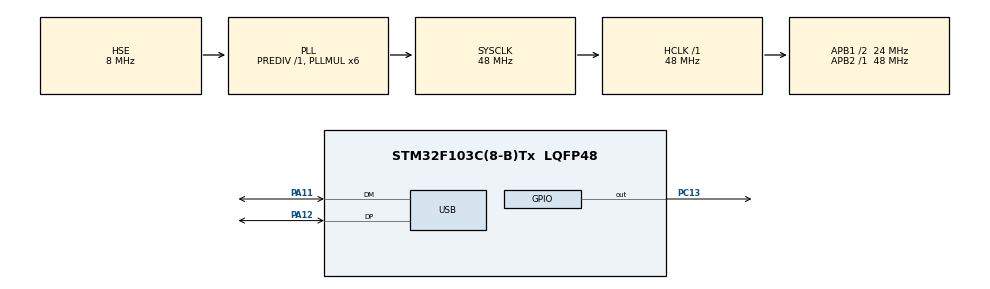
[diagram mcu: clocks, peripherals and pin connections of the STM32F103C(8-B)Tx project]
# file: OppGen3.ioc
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Mcu.Family=STM32F1
Mcu.Name=STM32F103C(8-B)Tx
Mcu.Package=LQFP48
NVIC.PriorityGroup=NVIC_PRIORITYGROUP_4
NVIC.USB_LP_CAN1_RX0_IRQn=true\:0\:0\:false\:false\:true\:false\:true
PA11.Mode=Device
PA11.Signal=USB_DM
PA12.Mode=Device
PA12.Signal=USB_DP
PA13.Mode=Serial_Wire
PA13.Signal=SYS_JTMS-SWDIO
PA14.Mode=Serial_Wire
PA14.Signal=SYS_JTCK-SWCLK
PC13-TAMPER-RTC.PinState=GPIO_PIN_SET
PC13-TAMPER-RTC.Signal=GPIO_Output
PD0-OSC_IN.Mode=HSE-External-Oscillator
PD0-OSC_IN.Signal=RCC_OSC_IN
PD1-OSC_OUT.Mode=HSE-External-Oscillator
PD1-OSC_OUT.Signal=RCC_OSC_OUT
ProjectManager.HeapSize=0x200
ProjectManager.StackSize=0x400
ProjectManager.TargetToolchain=SW4STM32
RCC.AHBFreq_Value=48000000
RCC.APB1CLKDivider=RCC_HCLK_DIV2
RCC.APB1Freq_Value=24000000
RCC.APB1TimFreq_Value=48000000
RCC.APB2Freq_Value=48000000
RCC.APB2TimFreq_Value=48000000
RCC.HCLKFreq_Value=48000000
RCC.PLLMUL=RCC_PLL_MUL6
RCC.SYSCLKFreq_VALUE=48000000
RCC.SYSCLKSource=RCC_SYSCLKSOURCE_PLLCLK
RCC.USBFreq_Value=48000000
USB_DEVICE.CLASS_NAME_FS=CDC
USB_DEVICE.VirtualMode=Cdc
USB_DEVICE.VirtualModeFS=Cdc_FS
VP_USB_DEVICE_VS_USB_DEVICE_CDC_FS.Mode=CDC_FS
board=custom

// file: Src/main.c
/* USER CODE BEGIN Header */
/*
 *===============================================================================
 *
 *                         OOOOOO
 *                       OOOOOOOOOO
 *      PPPPPPPPPPPPP   OOO      OOO   PPPPPPPPPPPPP
 *    PPPPPPPPPPPPPP   OOO        OOO   PPPPPPPPPPPPPP
 *   PPP         PPP   OOO        OOO   PPP         PPP
 *  PPP          PPP   OOO        OOO   PPP          PPP
 *  PPP          PPP   OOO        OOO   PPP          PPP
 *  PPP          PPP   OOO        OOO   PPP          PPP
 *   PPP         PPP   OOO        OOO   PPP         PPP
 *    PPPPPPPPPPPPPP   OOO        OOO   PPPPPPPPPPPPPP
 *     PPPPPPPPPPPPP   OOO        OOO   PPP
 *               PPP   OOO        OOO   PPP
 *               PPP   OOO        OOO   PPP
 *               PPP   OOO        OOO   PPP
 *               PPP    OOO      OOO    PPP
 *               PPP     OOOOOOOOOO     PPP
 *              PPPPP      OOOOOO      PPPPP
 *
 * @file:   main.c
 * @author: Hugh Spahr
 * @date:   9/21/2019
 *
 * @note:   Open Pinball Project
 *          Copyright© 2019, Hugh Spahr
 *
 *  This program is free software: you can redistribute it and/or modify
 *  it under the terms of the GNU General Public License as published by
 *  the Free Software Foundation, either version 3 of the License, or
 *  (at your option) any later version.
 *
 *  This program is distributed in the hope that it will be useful,
 *  but WITHOUT ANY WARRANTY; without even the implied warranty of
 *  MERCHANTABILITY or FITNESS FOR A PARTICULAR PURPOSE.  See the
 *  GNU General Public License for more details.
 *
 *  You should have received a copy of the GNU General Public License
 *  along with this program.  If not, see <http://www.gnu.org/licenses/>.
 *
 *===============================================================================
 */
/**
 * This is main file.  It initializes the tasks, and runs them.
 *
 *===============================================================================
 */
/* USER CODE END Header */

#include "main.h"
#include "usb_device.h"

/* USER CODE BEGIN Includes */
#include "Common/stdtypes.h"
#define GEN2G_INSTANTIATE
#include "Common/gen2glob.h"
#include "Common/neointf.h"
#include "Common/stdlintf.h"
#define INSTANTIATE_PROC
#include "Common/procdefs.h"
/* USER CODE END Includes */

void SystemClock_Config(void);
static void MX_GPIO_Init(void);

/* USER CODE BEGIN PFP */
/* HRS:  Debug */
void debug_save_nv_cfg();

/* Prototype declarations */
void timer_init();
void timer_overflow_isr();

void main_copy_flash_to_ram();
void main_call_wing_inits();

void digital_init();
void digital_task(void);
void digital_write_outputs();

void rs232proc_init();
void rs232proc_task();

void incand_task(void);

void fade_init();
void fade_start();
void fade_task();

void lampmtrx_task();

void servo_init();

/* USER CODE END PFP */

int main(void)
{

   /* MCU Configuration--------------------------------------------------------*/

   /* Reset of all peripherals, Initializes the Flash interface and the Systick. */
   HAL_Init();
#if GEN2G_DEBUG_PORT == 0
   __HAL_AFIO_REMAP_SWJ_DISABLE();
#endif

   /* Configure the system clock */
   SystemClock_Config();

   /* Initialize all configured peripherals */
   MX_GPIO_Init();
   MX_USB_DEVICE_Init();

   // HRS:  Start code here
   appStart.codeVers = GEN2G_CODE_VERS;

   /* Used for forcing the standard configuration onto the board.  If this is left on,
    * the programmed configuration will always be overwritten.
    */
#if 0
   debug_save_nv_cfg();
#endif

   fade_init();
   main_copy_flash_to_ram();
   main_call_wing_inits();
   fade_start();

   stdlser_init();
   rs232proc_init();

   /* Initialize tasks */
   timer_init();

   EnableInterrupts; /* Enable global interrupts. */

   /* USER CODE END 2 */

   /* Infinite loop */
   while (1)
   {

      /* USER CODE BEGIN 3 */
      timer_overflow_isr();
      fade_task();
      neo_task();
      digital_task();
      incand_task();
      lampmtrx_task();
      rs232proc_task();
      digital_write_outputs();
      /* USER CODE END 3 */
   }
}

void SystemClock_Config(void)
{
   RCC_OscInitTypeDef RCC_OscInitStruct = {0};
   RCC_ClkInitTypeDef RCC_ClkInitStruct = {0};
   RCC_PeriphCLKInitTypeDef PeriphClkInit = {0};

   /** Initializes the CPU, AHB and APB busses clocks
   */
   RCC_OscInitStruct.OscillatorType = RCC_OSCILLATORTYPE_HSE;
   RCC_OscInitStruct.HSEState = RCC_HSE_ON;
   RCC_OscInitStruct.HSEPredivValue = RCC_HSE_PREDIV_DIV1;
   RCC_OscInitStruct.HSIState = RCC_HSI_ON;
   RCC_OscInitStruct.PLL.PLLState = RCC_PLL_ON;
   RCC_OscInitStruct.PLL.PLLSource = RCC_PLLSOURCE_HSE;
   RCC_OscInitStruct.PLL.PLLMUL = RCC_PLL_MUL6;
   if (HAL_RCC_OscConfig(&RCC_OscInitStruct) != HAL_OK)
   {
      Error_Handler();
   }
   /** Initializes the CPU, AHB and APB busses clocks
   */
   RCC_ClkInitStruct.ClockType = RCC_CLOCKTYPE_HCLK|RCC_CLOCKTYPE_SYSCLK
                              |RCC_CLOCKTYPE_PCLK1|RCC_CLOCKTYPE_PCLK2;
   RCC_ClkInitStruct.SYSCLKSource = RCC_SYSCLKSOURCE_PLLCLK;
   RCC_ClkInitStruct.AHBCLKDivider = RCC_SYSCLK_DIV1;
   RCC_ClkInitStruct.APB1CLKDivider = RCC_HCLK_DIV2;
   RCC_ClkInitStruct.APB2CLKDivider = RCC_HCLK_DIV1;

   if (HAL_RCC_ClockConfig(&RCC_ClkInitStruct, FLASH_LATENCY_1) != HAL_OK)
   {
      Error_Handler();
   }
   PeriphClkInit.PeriphClockSelection = RCC_PERIPHCLK_USB;
   PeriphClkInit.UsbClockSelection = RCC_USBCLKSOURCE_PLL;
   if (HAL_RCCEx_PeriphCLKConfig(&PeriphClkInit) != HAL_OK)
   {
      Error_Handler();
   }
}

static void MX_GPIO_Init(void)
{
   /* GPIO Ports Clock Enable */
   __HAL_RCC_GPIOC_CLK_ENABLE();
   __HAL_RCC_GPIOD_CLK_ENABLE();
   __HAL_RCC_GPIOB_CLK_ENABLE();
   __HAL_RCC_GPIOA_CLK_ENABLE();
}

/* USER CODE BEGIN 4 */
/*
 * ===============================================================================
 *
 * Name: main_copy_flash_to_ram
 *
 * ===============================================================================
 */
/**
 * Copy flash to RAM
 *
 * Check if the flash settings are valid.  If so, copy the information into RAM.
 *
 * @param   None
 * @param   None
 * @return  None
 *
 * @pre     None
 * @note    None
 *
 * ===============================================================================
 */
void main_copy_flash_to_ram()
{
   U8                         crc;
   U32                        *src_p;
   U32                        *dst_p;
   INT                        index;

   /* Init gen2g structure */
   gen2g_info.typeWingBrds = 0;
   gen2g_info.crcErr = 0;
   gen2g_info.statusBlink = GEN2G_STAT_LED_ON;
   gen2g_info.error = NO_ERRORS;
   gen2g_info.validCfg = FALSE;
   gen2g_info.haveNeo = FALSE;
   gen2g_info.haveSpi = FALSE;
   gen2g_info.haveFade = FALSE;
   gen2g_info.haveLampMtrx = FALSE;
   gen2g_info.freeCfg_p = &gen2g_info.nvCfgInfo.cfgData[0];
   gen2g_info.prodId = gen2g_persist_p->prodId;
   gen2g_info.serNum = gen2g_persist_p->serNum;
   for (index = 0; index < RS232I_NUM_GEN2_INP; index++)
   {
      gen2g_info.inpTimestamp[index] = 0;
   }

   while (!gen2g_info.validCfg)
   {
      /* Test if wing cfg have valid settings */
      crc = 0xff;
      stdlser_calc_crc8(&crc, GEN2G_NV_PARM_SIZE, (U8 *)gen2g_nv_cfg_p->wingCfg);
      if (crc == gen2g_nv_cfg_p->nvCfgCrc)
      {
         gen2g_info.validCfg = TRUE;

         /* Copy the wing configuration */
         for (src_p = (U32 *)gen2g_nv_cfg_p, dst_p = (U32 *)&gen2g_info.nvCfgInfo;
            src_p < (U32 *)(GEN2G_CFG_TBL + sizeof(GEN2G_NV_CFG_T)); )
         {
            *dst_p++ = *src_p++;
         }
      }
      else
      {
         /* Config CRC8 failed, save a valid configuration */
         debug_save_nv_cfg();
         gen2g_info.validCfg = FALSE;
      }
   }
} /* End main_copy_flash_to_ram */

/*
 * ===============================================================================
 *
 * Name: main_call_wing_inits
 *
 * ===============================================================================
 */
/**
 * Call wing board init functions
 *
 * If the configuration is valid, create wing board type mask, and call init
 * functions.
 *
 * @param   None
 * @param   None
 * @return  None
 *
 * @pre     None
 * @note    None
 *
 * ===============================================================================
 */
void main_call_wing_inits()
{
   INT                        index;

   if (gen2g_info.validCfg)
   {
      /* Walk through the wing boards and create bit mask of wing board types */
      for (index = 0; index < RS232I_NUM_WING; index++)
      {
         if (gen2g_info.nvCfgInfo.wingCfg[index] != WING_UNUSED)
         {
            gen2g_info.typeWingBrds |= (1 << gen2g_info.nvCfgInfo.wingCfg[index]);
         }
      }

      /* Walk through types and call init functions using jump table */
      digital_init();
      for (index = WING_UNUSED + 1; index < MAX_WING_TYPES; index++)
      {
         if (((gen2g_info.typeWingBrds & (1 << index)) != 0) &&
            (GEN2G_INIT_FP[index] != NULL))
         {
            GEN2G_INIT_FP[index]();
         }
      }
      servo_init();
   }
} /* End main_call_wing_inits */
/* USER CODE END 4 */

void Error_Handler(void)
{
}

/************************ (C) COPYRIGHT STMicroelectronics *****END OF FILE****/
